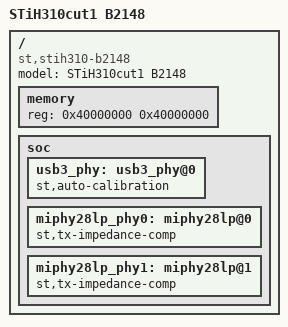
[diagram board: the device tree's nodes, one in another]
/*
 * Copyright (C) 2014 STMicroelectronics Limited.
 * Author: Giuseppe Condorelli <giuseppe.condorelli@st.com>
 *
 * This program is free software; you can redistribute it and/or modify
 * it under the terms of the GNU General Public License version 2 as
 * publishhed by the Free Software Foundation.
 */
/dts-v1/;

#include "stih410cut1.dtsi"
#include "stihxxx-b2148.dtsi"

/ {
	model = "STiH310cut1 B2148";
	compatible = "st,stih310-b2148", "st,stih310";

	memory {
		device_type = "memory";
		reg = <0x40000000 0x40000000>;
	};

	soc {
		usb3_phy: usb3_phy@0 {
			st,auto-calibration;
		};

		/* set tx impedance compensation */
		miphy28lp_phy0: miphy28lp@0 {
			st,tx-impedance-comp;
		};

		miphy28lp_phy1: miphy28lp@1 {
			st,tx-impedance-comp;
		};
	};
};
